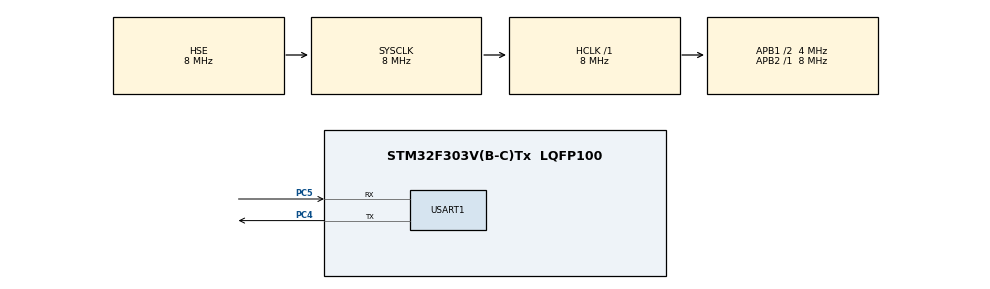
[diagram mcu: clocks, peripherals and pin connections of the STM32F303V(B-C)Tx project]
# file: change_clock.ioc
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Mcu.Family=STM32F3
Mcu.Name=STM32F303V(B-C)Tx
Mcu.Package=LQFP100
NVIC.PriorityGroup=NVIC_PRIORITYGROUP_4
NVIC.RTC_WKUP_IRQn=true\:0\:0\:false\:false\:true\:true\:true\:true
PC4.Mode=Asynchronous
PC4.Signal=USART1_TX
PC5.Mode=Asynchronous
PC5.Signal=USART1_RX
PF0-OSC_IN.Mode=HSE-External-Oscillator
PF0-OSC_IN.Signal=RCC_OSC_IN
PF1-OSC_OUT.Mode=HSE-External-Oscillator
PF1-OSC_OUT.Signal=RCC_OSC_OUT
ProjectManager.HeapSize=0x200
ProjectManager.StackSize=0x400
ProjectManager.TargetToolchain=STM32CubeIDE
RCC.AHBFreq_Value=8000000
RCC.APB1CLKDivider=RCC_HCLK_DIV2
RCC.APB1Freq_Value=4000000
RCC.APB1TimFreq_Value=8000000
RCC.APB2Freq_Value=8000000
RCC.APB2TimFreq_Value=8000000
RCC.CortexFreq_Value=8000000
RCC.HCLKFreq_Value=8000000
RCC.HSE_VALUE=8000000
RCC.HSI_VALUE=8000000
RCC.LSE_VALUE=32768
RCC.PLLSourceVirtual=RCC_PLLSOURCE_HSE
RCC.SYSCLKFreq_VALUE=8000000
RCC.SYSCLKSourceVirtual=RCC_SYSCLKSOURCE_HSE
RCC.USBFreq_Value=16000000
USART1.VirtualMode-Asynchronous=VM_ASYNC
VP_RTC_VS_RTC_Activate.Mode=RTC_Enabled
VP_RTC_VS_RTC_WakeUp_intern.Mode=WakeUp
VP_TIM2_VS_ClockSourceINT.Mode=Internal
board=custom

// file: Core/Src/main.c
/* USER CODE BEGIN Header */
/**
  ******************************************************************************
  * @file           : main.c
  * @brief          : Main program body
  ******************************************************************************
  * @attention
  *
  * Copyright (c) 2023 STMicroelectronics.
  * All rights reserved.
  *
  * This software is licensed under terms that can be found in the LICENSE file
  * in the root directory of this software component.
  * If no LICENSE file comes with this software, it is provided AS-IS.
  *
  ******************************************************************************
  */
/* USER CODE END Header */
#include "main.h"

RTC_HandleTypeDef hrtc;

TIM_HandleTypeDef htim2;

UART_HandleTypeDef huart1;

void SystemClock_Config(void);
static void MX_GPIO_Init(void);
static void MX_TIM2_Init(void);
static void MX_USART1_UART_Init(void);
static void MX_RTC_Init(void);
/* USER CODE BEGIN PFP */
static void SystemClockHSE_Config(void);
static void SystemClockHSI_Config(void);
/* USER CODE END PFP */

/* USER CODE BEGIN 0 */
void Sleep(int time)
{
  HAL_SuspendTick();
  uint32_t counter = time*2;/*divide by (16/32)*/
  HAL_RTCEx_SetWakeUpTimer_IT(&hrtc, counter, RTC_WAKEUPCLOCK_RTCCLK_DIV16);

  /* Enter sleep mode */
  HAL_PWR_EnterSLEEPMode(PWR_MAINREGULATOR_ON, PWR_STOPENTRY_WFI);
  HAL_RTCEx_DeactivateWakeUpTimer(&hrtc);
  HAL_ResumeTick();
}
/* USER CODE END 0 */

int main(void)
{

  /* MCU Configuration--------------------------------------------------------*/

  /* Reset of all peripherals, Initializes the Flash interface and the Systick. */
  HAL_Init();

  /* Configure the system clock */
  SystemClock_Config();

  /* Initialize all configured peripherals */
  MX_GPIO_Init();
  MX_TIM2_Init();
  MX_USART1_UART_Init();
  MX_RTC_Init();
  /* USER CODE BEGIN 2 */
  HAL_TIM_Base_Start(&htim2);
  /*int f1 = HAL_RCC_GetSysClockFreq();
  //__HAL_RCC_SYSCLK_CONFIG(RCC_SYSCLKSOURCE_STATUS_HSI);

  int pllon_addr = (__IO uint32_t *)RCC_CR_PLLON_BB;
  int pllon_val1 = *(__IO uint32_t *)RCC_CR_PLLON_BB;
  __HAL_RCC_PLL_DISABLE();
  int f2 = HAL_RCC_GetSysClockFreq();
  int pllon_val2 = *(__IO uint32_t *)RCC_CR_PLLON_BB;
  *(__IO uint32_t *)RCC_CFGR_PLLMUL_BB = RCC_CFGR_PLLMUL16;
  __HAL_RCC_PLL_CONFIG(RCC_PLLSOURCE_HSI,RCC_PLL_MUL16);
  __HAL_RCC_PLL_ENABLE();
  int pllmul_val2 = *(__IO uint32_t *)RCC_CFGR_PLLMUL_BB;
  //__HAL_RCC_SYSCLK_CONFIG(RCC_SYSCLKSOURCE_STATUS_PLLCLK);
  int f3 = HAL_RCC_GetSysClockFreq();*/
  /* USER CODE END 2 */

  /* Infinite loop */
  /* USER CODE BEGIN WHILE */

  uint8_t msg[60] = {"\o"};
  sprintf(msg, "\n START \n");
  HAL_UART_Transmit(&huart1, msg, sizeof(msg), 0xFFFF);
  int f1 = HAL_RCC_GetSysClockFreq();
  Sleep(200);
  int t1 = TIM2 -> CNT;
  SystemClockHSI_Config();
  int t2 = TIM2 -> CNT;
  Sleep(200);
  int f2 = HAL_RCC_GetSysClockFreq();
  MX_USART1_UART_Init();
  sprintf(msg, "f1 : %d | f2 : %d | t : %d \n\n", f1/1000000, f2/1000000, t2-t1);
  HAL_UART_Transmit(&huart1, msg, sizeof(msg), 0xFFFF);
  //HAL_PWR_EnterSTOPMode(PWR_MAINREGULATOR_ON, PWR_STOPENTRY_WFI);
    /* USER CODE END WHILE */

}

void SystemClock_Config(void)
{
  RCC_OscInitTypeDef RCC_OscInitStruct = {0};
  RCC_ClkInitTypeDef RCC_ClkInitStruct = {0};
  RCC_PeriphCLKInitTypeDef PeriphClkInit = {0};

  /** Initializes the RCC Oscillators according to the specified parameters
  * in the RCC_OscInitTypeDef structure.
  */
  RCC_OscInitStruct.OscillatorType = RCC_OSCILLATORTYPE_LSI|RCC_OSCILLATORTYPE_HSE;
  RCC_OscInitStruct.HSEState = RCC_HSE_ON;
  RCC_OscInitStruct.HSIState = RCC_HSI_ON;
  RCC_OscInitStruct.LSIState = RCC_LSI_ON;
  RCC_OscInitStruct.PLL.PLLState = RCC_PLL_NONE;
  if (HAL_RCC_OscConfig(&RCC_OscInitStruct) != HAL_OK)
  {
    Error_Handler();
  }

  /** Initializes the CPU, AHB and APB buses clocks
  */
  RCC_ClkInitStruct.ClockType = RCC_CLOCKTYPE_HCLK|RCC_CLOCKTYPE_SYSCLK
                              |RCC_CLOCKTYPE_PCLK1|RCC_CLOCKTYPE_PCLK2;
  RCC_ClkInitStruct.SYSCLKSource = RCC_SYSCLKSOURCE_HSE;
  RCC_ClkInitStruct.AHBCLKDivider = RCC_SYSCLK_DIV1;
  RCC_ClkInitStruct.APB1CLKDivider = RCC_HCLK_DIV2;
  RCC_ClkInitStruct.APB2CLKDivider = RCC_HCLK_DIV1;

  if (HAL_RCC_ClockConfig(&RCC_ClkInitStruct, FLASH_LATENCY_0) != HAL_OK)
  {
    Error_Handler();
  }
  PeriphClkInit.PeriphClockSelection = RCC_PERIPHCLK_USART1|RCC_PERIPHCLK_RTC;
  PeriphClkInit.Usart1ClockSelection = RCC_USART1CLKSOURCE_PCLK2;
  PeriphClkInit.RTCClockSelection = RCC_RTCCLKSOURCE_LSI;
  if (HAL_RCCEx_PeriphCLKConfig(&PeriphClkInit) != HAL_OK)
  {
    Error_Handler();
  }
}

static void MX_RTC_Init(void)
{

  /** Initialize RTC Only
  */
  hrtc.Instance = RTC;
  hrtc.Init.HourFormat = RTC_HOURFORMAT_24;
  hrtc.Init.AsynchPrediv = 127;
  hrtc.Init.SynchPrediv = 255;
  hrtc.Init.OutPut = RTC_OUTPUT_DISABLE;
  hrtc.Init.OutPutPolarity = RTC_OUTPUT_POLARITY_HIGH;
  hrtc.Init.OutPutType = RTC_OUTPUT_TYPE_OPENDRAIN;
  if (HAL_RTC_Init(&hrtc) != HAL_OK)
  {
    Error_Handler();
  }

  /** Enable the WakeUp
  */
  if (HAL_RTCEx_SetWakeUpTimer_IT(&hrtc, 0, RTC_WAKEUPCLOCK_RTCCLK_DIV16) != HAL_OK)
  {
    Error_Handler();
  }

}

static void MX_TIM2_Init(void)
{

  TIM_ClockConfigTypeDef sClockSourceConfig = {0};
  TIM_MasterConfigTypeDef sMasterConfig = {0};

  htim2.Instance = TIM2;
  htim2.Init.Prescaler = 0;
  htim2.Init.CounterMode = TIM_COUNTERMODE_UP;
  htim2.Init.Period = 4294967295;
  htim2.Init.ClockDivision = TIM_CLOCKDIVISION_DIV1;
  htim2.Init.AutoReloadPreload = TIM_AUTORELOAD_PRELOAD_DISABLE;
  if (HAL_TIM_Base_Init(&htim2) != HAL_OK)
  {
    Error_Handler();
  }
  sClockSourceConfig.ClockSource = TIM_CLOCKSOURCE_INTERNAL;
  if (HAL_TIM_ConfigClockSource(&htim2, &sClockSourceConfig) != HAL_OK)
  {
    Error_Handler();
  }
  sMasterConfig.MasterOutputTrigger = TIM_TRGO_RESET;
  sMasterConfig.MasterSlaveMode = TIM_MASTERSLAVEMODE_DISABLE;
  if (HAL_TIMEx_MasterConfigSynchronization(&htim2, &sMasterConfig) != HAL_OK)
  {
    Error_Handler();
  }

}

static void MX_USART1_UART_Init(void)
{

  huart1.Instance = USART1;
  huart1.Init.BaudRate = 38400;
  huart1.Init.WordLength = UART_WORDLENGTH_8B;
  huart1.Init.StopBits = UART_STOPBITS_1;
  huart1.Init.Parity = UART_PARITY_NONE;
  huart1.Init.Mode = UART_MODE_TX_RX;
  huart1.Init.HwFlowCtl = UART_HWCONTROL_NONE;
  huart1.Init.OverSampling = UART_OVERSAMPLING_16;
  huart1.Init.OneBitSampling = UART_ONE_BIT_SAMPLE_DISABLE;
  huart1.AdvancedInit.AdvFeatureInit = UART_ADVFEATURE_NO_INIT;
  if (HAL_UART_Init(&huart1) != HAL_OK)
  {
    Error_Handler();
  }

}

static void MX_GPIO_Init(void)
{

  /* GPIO Ports Clock Enable */
  __HAL_RCC_GPIOF_CLK_ENABLE();
  __HAL_RCC_GPIOC_CLK_ENABLE();

}

/* USER CODE BEGIN 4 */
static void SystemClockHSE_Config(void)
{
  RCC_ClkInitTypeDef RCC_ClkInitStruct = {0};
  RCC_OscInitTypeDef RCC_OscInitStruct = {0};

  /* -1- Select HSI as system clock source to allow modification of the PLL configuration */
  RCC_ClkInitStruct.ClockType = RCC_CLOCKTYPE_SYSCLK;
  RCC_ClkInitStruct.SYSCLKSource = RCC_SYSCLKSOURCE_HSI;
  if (HAL_RCC_ClockConfig(&RCC_ClkInitStruct, FLASH_LATENCY_1) != HAL_OK)
  {
    /* Initialization Error */
    Error_Handler();
  }

  /* -2- Enable HSE  Oscillator, select it as PLL source and finally activate the PLL */
  RCC_OscInitStruct.OscillatorType  = RCC_OSCILLATORTYPE_HSE;
  RCC_OscInitStruct.HSEState        = RCC_HSE_ON;
  RCC_OscInitStruct.HSEPredivValue  = RCC_HSE_PREDIV_DIV1;
  RCC_OscInitStruct.PLL.PLLSource   = RCC_PLLSOURCE_HSE;
  RCC_OscInitStruct.PLL.PLLState    = RCC_PLL_ON;
  RCC_OscInitStruct.PLL.PLLMUL      = RCC_PLL_MUL9;
  if (HAL_RCC_OscConfig(&RCC_OscInitStruct) != HAL_OK)
  {
    /* Initialization Error */
    Error_Handler();
  }

  /* -3- Select the PLL as system clock source and configure the HCLK, PCLK1 and PCLK2 clocks dividers */
  RCC_ClkInitStruct.ClockType       = (RCC_CLOCKTYPE_SYSCLK | RCC_CLOCKTYPE_HCLK | RCC_CLOCKTYPE_PCLK1 | RCC_CLOCKTYPE_PCLK2);
  RCC_ClkInitStruct.SYSCLKSource    = RCC_SYSCLKSOURCE_PLLCLK;
  RCC_ClkInitStruct.AHBCLKDivider   = RCC_SYSCLK_DIV1;
  RCC_ClkInitStruct.APB1CLKDivider  = RCC_HCLK_DIV2;
  RCC_ClkInitStruct.APB2CLKDivider  = RCC_HCLK_DIV1;
  if (HAL_RCC_ClockConfig(&RCC_ClkInitStruct, FLASH_LATENCY_2) != HAL_OK)
  {
    /* Initialization Error */
    Error_Handler();
  }

  /* -4- Optional: Disable HSI Oscillator (if the HSI is no more needed by the application)*/
  RCC_OscInitStruct.OscillatorType  = RCC_OSCILLATORTYPE_HSI;
  RCC_OscInitStruct.HSIState        = RCC_HSI_OFF;
  RCC_OscInitStruct.PLL.PLLState    = RCC_PLL_NONE;
  if (HAL_RCC_OscConfig(&RCC_OscInitStruct) != HAL_OK)
  {
    /* Initialization Error */
    Error_Handler();
  }
}

static void SystemClockHSI_Config(void)
{
  RCC_ClkInitTypeDef RCC_ClkInitStruct = {0};
  RCC_OscInitTypeDef RCC_OscInitStruct = {0};

  /* -1- Select HSE  as system clock source to allow modification of the PLL configuration */
  RCC_ClkInitStruct.ClockType       = RCC_CLOCKTYPE_SYSCLK;
  RCC_ClkInitStruct.SYSCLKSource    = RCC_SYSCLKSOURCE_HSE;
  if (HAL_RCC_ClockConfig(&RCC_ClkInitStruct, FLASH_LATENCY_1) != HAL_OK)
  {
    /* Initialization Error */
    Error_Handler();
  }

  /* -2- Enable HSI Oscillator, select it as PLL source and finally activate the PLL */
  RCC_OscInitStruct.OscillatorType    = RCC_OSCILLATORTYPE_HSI;
  RCC_OscInitStruct.HSIState          = RCC_HSI_ON;
  RCC_OscInitStruct.HSICalibrationValue  = RCC_HSICALIBRATION_DEFAULT;
  RCC_OscInitStruct.PLL.PLLState      = RCC_PLL_ON;
  RCC_OscInitStruct.PLL.PLLSource     = RCC_PLLSOURCE_HSI;
  /* PLL source is the HSI frequency divided by 2 */
  RCC_OscInitStruct.PLL.PLLMUL       = RCC_PLL_MUL16;
  if (HAL_RCC_OscConfig(&RCC_OscInitStruct) != HAL_OK)
  {
    /* Initialization Error */
    Error_Handler();
  }

  /* -3- Select the PLL as system clock source and configure the HCLK, PCLK1 and PCLK2 clocks dividers */
  RCC_ClkInitStruct.ClockType       = (RCC_CLOCKTYPE_SYSCLK | RCC_CLOCKTYPE_HCLK | RCC_CLOCKTYPE_PCLK1 | RCC_CLOCKTYPE_PCLK2);
  RCC_ClkInitStruct.SYSCLKSource    = RCC_SYSCLKSOURCE_PLLCLK;
  RCC_ClkInitStruct.AHBCLKDivider   = RCC_SYSCLK_DIV1;
  RCC_ClkInitStruct.APB1CLKDivider  = RCC_HCLK_DIV2;
  RCC_ClkInitStruct.APB2CLKDivider  = RCC_HCLK_DIV1;
  if (HAL_RCC_ClockConfig(&RCC_ClkInitStruct, FLASH_LATENCY_2) != HAL_OK)
  {
    /* Initialization Error */
    Error_Handler();
  }

  /* -4- Optional: Disable HSE  Oscillator (if the HSE  is no more needed by the application) */
  RCC_OscInitStruct.OscillatorType  = RCC_OSCILLATORTYPE_HSE;
  RCC_OscInitStruct.HSEState        = RCC_HSE_OFF;
  RCC_OscInitStruct.PLL.PLLState    = RCC_PLL_NONE;
  if (HAL_RCC_OscConfig(&RCC_OscInitStruct) != HAL_OK)
  {
    /* Initialization Error */
    Error_Handler();
  }
}
/* USER CODE END 4 */

void Error_Handler(void)
{
  __disable_irq();
  while (1)
  {
  }
}
